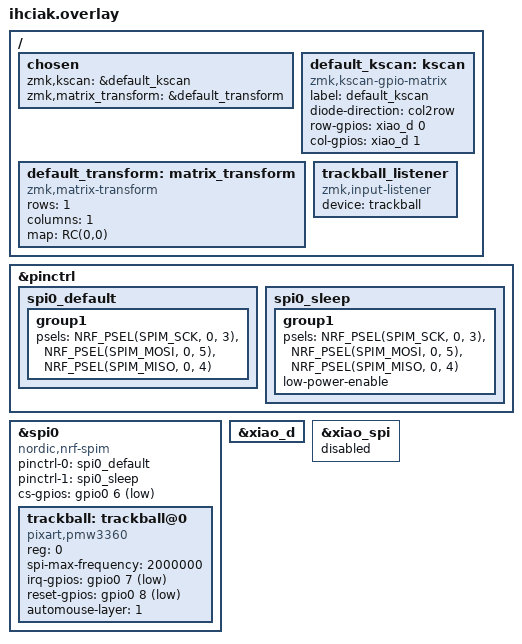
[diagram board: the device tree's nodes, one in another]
/*
 * Copyright (c) 2025 The ZMK Contributors
 * SPDX-License-Identifier: MIT
 */

#include <dt-bindings/zmk/matrix_transform.h>
#include <dt-bindings/zmk/mouse.h>

/ {
    chosen {
        zmk,kscan = &default_kscan;
        zmk,matrix_transform = &default_transform;
    };

    default_kscan: kscan {
        compatible = "zmk,kscan-gpio-matrix";
        label = "default_kscan";
        diode-direction = "col2row";

        // キーマトリックスの行と列の設定
        // 実際のキーボードのピン接続に合わせて調整してください
        row-gpios = <&xiao_d 0 (GPIO_ACTIVE_HIGH | GPIO_PULL_DOWN)>;
        col-gpios = <&xiao_d 1 GPIO_ACTIVE_HIGH>;
    };

    default_transform: matrix_transform {
        compatible = "zmk,matrix-transform";
        rows = <1>;
        columns = <1>;
        map = <
            RC(0,0)
        >;
    };
};

&pinctrl {
    spi0_default: spi0_default {
        group1 {
            psels = <NRF_PSEL(SPIM_SCK, 0, 3)>,  // D3
                   <NRF_PSEL(SPIM_MOSI, 0, 5)>,  // D5
                   <NRF_PSEL(SPIM_MISO, 0, 4)>;  // D4
        };
    };

    spi0_sleep: spi0_sleep {
        group1 {
            psels = <NRF_PSEL(SPIM_SCK, 0, 3)>,  // D3
                   <NRF_PSEL(SPIM_MOSI, 0, 5)>,  // D5
                   <NRF_PSEL(SPIM_MISO, 0, 4)>;  // D4
            low-power-enable;
        };
    };
};

&spi0 {
    status = "okay";
    compatible = "nordic,nrf-spim";
    pinctrl-0 = <&spi0_default>;
    pinctrl-1 = <&spi0_sleep>;
    pinctrl-names = "default", "sleep";
    cs-gpios = <&gpio0 6 GPIO_ACTIVE_LOW>;  // D6

    trackball: trackball@0 {
        status = "okay";
        compatible = "pixart,pmw3360";
        reg = <0>;
        spi-max-frequency = <2000000>;
        irq-gpios = <&gpio0 7 (GPIO_ACTIVE_LOW | GPIO_PULL_UP)>;  // D7
        reset-gpios = <&gpio0 8 GPIO_ACTIVE_LOW>;  // D8

        /* オプション機能 */
        automouse-layer = <1>;  // トラックボール動作時に自動で有効になるレイヤー
    };
};

/ {
  trackball_listener {
    compatible = "zmk,input-listener";
    device = <&trackball>;
  };
};

// Xiao BLEのピン定義（Seeeduino XIAO BLE用）
&xiao_d {
    status = "okay";
};

&xiao_spi {
    status = "disabled"; // 私たちはSPI0を直接使うため
};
